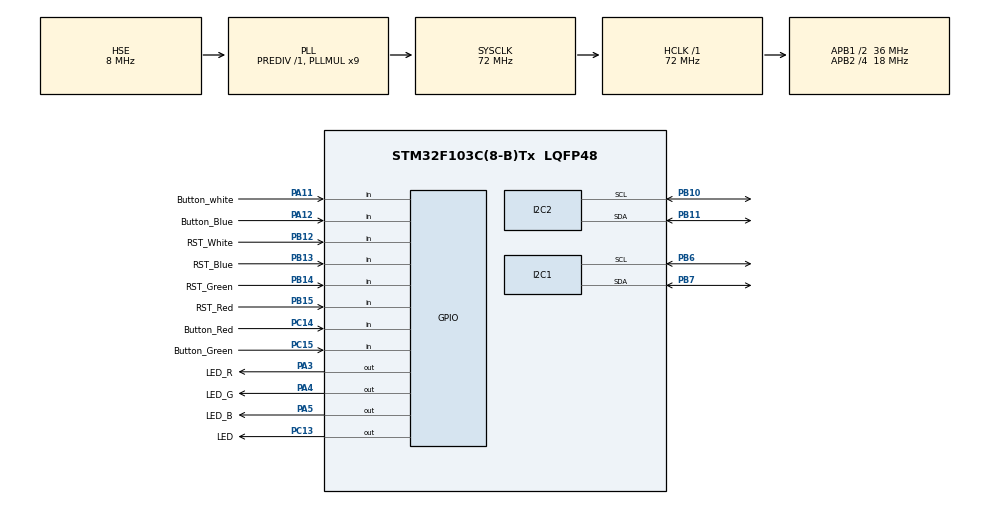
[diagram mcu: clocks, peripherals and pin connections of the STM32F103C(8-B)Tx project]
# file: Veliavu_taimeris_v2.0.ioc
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Mcu.Family=STM32F1
RCC.PLLSourceVirtual=RCC_PLLSOURCE_HSE
PD1-OSC_OUT.Mode=HSE-External-Oscillator
PB10.Mode=I2C
PB14.GPIO_Label=RST_Green
PC13-TAMPER-RTC.Signal=GPIO_Output
PA11.GPIO_Label=Button_white
PD0-OSC_IN.Signal=RCC_OSC_IN
PA11.GPIO_PuPd=GPIO_PULLUP
RCC.APB1CLKDivider=RCC_HCLK_DIV2
PC14-OSC32_IN.Signal=GPIO_Input
PB13.GPIO_Label=RST_Blue
PB11.Signal=I2C2_SDA
PB13.Signal=GPIO_Input
PB15.Signal=GPIO_Input
PC15-OSC32_OUT.GPIO_Label=Button_Green
PA12.GPIO_Label=Button_Blue
RCC.SYSCLKSource=RCC_SYSCLKSOURCE_PLLCLK
ProjectManager.StackSize=0x400
PD1-OSC_OUT.Signal=RCC_OSC_OUT
PA13.Signal=SYS_JTMS-SWDIO
PA12.Signal=GPIO_Input
PB11.Mode=I2C
ProjectManager.TargetToolchain=SW4STM32
RCC.HCLKFreq_Value=72000000
RCC.APB2TimFreq_Value=36000000
PB6.Signal=I2C1_SCL
PB6.Mode=I2C
RCC.USBFreq_Value=72000000
PC15-OSC32_OUT.Signal=GPIO_Input
RCC.AHBFreq_Value=72000000
PD0-OSC_IN.Mode=HSE-External-Oscillator
PB10.Signal=I2C2_SCL
PB14.Signal=GPIO_Input
PA5.Signal=GPIO_Output
board=custom
PC13-TAMPER-RTC.GPIO_Label=LED
RCC.PLLMUL=RCC_PLL_MUL9
PB12.GPIO_Label=RST_White
PB13.GPIO_PuPd=GPIO_PULLUP
RCC.APB2Freq_Value=18000000
PB15.GPIO_Label=RST_Red
PA14.Mode=Serial_Wire
PC15-OSC32_OUT.GPIO_PuPd=GPIO_PULLUP
PB7.Signal=I2C1_SDA
PA13.Mode=Serial_Wire
Mcu.Name=STM32F103C(8-B)Tx
PA4.Signal=GPIO_Output
RCC.SYSCLKFreq_VALUE=72000000
Mcu.Package=LQFP48
PB14.GPIO_PuPd=GPIO_PULLUP
PA5.GPIO_Label=LED_B
PB15.GPIO_PuPd=GPIO_PULLUP
PA11.Signal=GPIO_Input
PB7.Mode=I2C
PA14.Signal=SYS_JTCK-SWCLK
ProjectManager.HeapSize=0x200
NVIC.PriorityGroup=NVIC_PRIORITYGROUP_4
RCC.APB2CLKDivider=RCC_HCLK_DIV4
RCC.APB1TimFreq_Value=72000000
PC14-OSC32_IN.GPIO_PuPd=GPIO_PULLUP
PC14-OSC32_IN.GPIO_Label=Button_Red
PB12.GPIO_PuPd=GPIO_PULLUP
PA12.GPIO_PuPd=GPIO_PULLUP
RCC.APB1Freq_Value=36000000
PA4.GPIO_Label=LED_G
PB12.Signal=GPIO_Input
PA3.GPIO_Label=LED_R
PA3.Signal=GPIO_Output

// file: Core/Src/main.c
/* USER CODE BEGIN Header */
/**
  ******************************************************************************
  * @file           : main.c
  * @brief          : Main program body
  ******************************************************************************
  * @attention
  *
  * <h2><center>&copy; Copyright (c) 2021 STMicroelectronics.
  * All rights reserved.</center></h2>
  *
  * This software component is licensed by ST under BSD 3-Clause license,
  * the "License"; You may not use this file except in compliance with the
  * License. You may obtain a copy of the License at:
  *                        opensource.org/licenses/BSD-3-Clause
  *
  ******************************************************************************
  */
/* USER CODE END Header */
#include "main.h"

/* USER CODE BEGIN Includes */
#include "timer.h"
/* USER CODE END Includes */

I2C_HandleTypeDef hi2c1;
I2C_HandleTypeDef hi2c2;

void SystemClock_Config(void);
static void MX_GPIO_Init(void);
static void MX_I2C1_Init(void);
static void MX_I2C2_Init(void);

int main(void)
{

  /* MCU Configuration--------------------------------------------------------*/

  /* Reset of all peripherals, Initializes the Flash interface and the Systick. */
  HAL_Init();

  /* Configure the system clock */
  SystemClock_Config();

  /* Initialize all configured peripherals */
  MX_GPIO_Init();
  MX_I2C1_Init();
  MX_I2C2_Init();
  /* USER CODE BEGIN 2 */
  timer_ini();
  /* USER CODE END 2 */

  /* Infinite loop */
  /* USER CODE BEGIN WHILE */
  while (1)
  {
	  timer_rst();
	  red_team();
	  timer_rst();
	  green_team();
	  timer_rst();
	  blue_team();
	  timer_rst();
	  white_team();
    /* USER CODE END WHILE */

  }
}

void SystemClock_Config(void)
{
  RCC_OscInitTypeDef RCC_OscInitStruct = {0};
  RCC_ClkInitTypeDef RCC_ClkInitStruct = {0};

  /** Initializes the RCC Oscillators according to the specified parameters
  * in the RCC_OscInitTypeDef structure.
  */
  RCC_OscInitStruct.OscillatorType = RCC_OSCILLATORTYPE_HSE;
  RCC_OscInitStruct.HSEState = RCC_HSE_ON;
  RCC_OscInitStruct.HSEPredivValue = RCC_HSE_PREDIV_DIV1;
  RCC_OscInitStruct.HSIState = RCC_HSI_ON;
  RCC_OscInitStruct.PLL.PLLState = RCC_PLL_ON;
  RCC_OscInitStruct.PLL.PLLSource = RCC_PLLSOURCE_HSE;
  RCC_OscInitStruct.PLL.PLLMUL = RCC_PLL_MUL9;
  if (HAL_RCC_OscConfig(&RCC_OscInitStruct) != HAL_OK)
  {
    Error_Handler();
  }
  /** Initializes the CPU, AHB and APB buses clocks
  */
  RCC_ClkInitStruct.ClockType = RCC_CLOCKTYPE_HCLK|RCC_CLOCKTYPE_SYSCLK
                              |RCC_CLOCKTYPE_PCLK1|RCC_CLOCKTYPE_PCLK2;
  RCC_ClkInitStruct.SYSCLKSource = RCC_SYSCLKSOURCE_PLLCLK;
  RCC_ClkInitStruct.AHBCLKDivider = RCC_SYSCLK_DIV1;
  RCC_ClkInitStruct.APB1CLKDivider = RCC_HCLK_DIV2;
  RCC_ClkInitStruct.APB2CLKDivider = RCC_HCLK_DIV4;

  if (HAL_RCC_ClockConfig(&RCC_ClkInitStruct, FLASH_LATENCY_2) != HAL_OK)
  {
    Error_Handler();
  }
}

static void MX_I2C1_Init(void)
{

  hi2c1.Instance = I2C1;
  hi2c1.Init.ClockSpeed = 100000;
  hi2c1.Init.DutyCycle = I2C_DUTYCYCLE_2;
  hi2c1.Init.OwnAddress1 = 0;
  hi2c1.Init.AddressingMode = I2C_ADDRESSINGMODE_7BIT;
  hi2c1.Init.DualAddressMode = I2C_DUALADDRESS_DISABLE;
  hi2c1.Init.OwnAddress2 = 0;
  hi2c1.Init.GeneralCallMode = I2C_GENERALCALL_DISABLE;
  hi2c1.Init.NoStretchMode = I2C_NOSTRETCH_DISABLE;
  if (HAL_I2C_Init(&hi2c1) != HAL_OK)
  {
    Error_Handler();
  }

}

static void MX_I2C2_Init(void)
{

  hi2c2.Instance = I2C2;
  hi2c2.Init.ClockSpeed = 100000;
  hi2c2.Init.DutyCycle = I2C_DUTYCYCLE_2;
  hi2c2.Init.OwnAddress1 = 0;
  hi2c2.Init.AddressingMode = I2C_ADDRESSINGMODE_7BIT;
  hi2c2.Init.DualAddressMode = I2C_DUALADDRESS_DISABLE;
  hi2c2.Init.OwnAddress2 = 0;
  hi2c2.Init.GeneralCallMode = I2C_GENERALCALL_DISABLE;
  hi2c2.Init.NoStretchMode = I2C_NOSTRETCH_DISABLE;
  if (HAL_I2C_Init(&hi2c2) != HAL_OK)
  {
    Error_Handler();
  }

}

static void MX_GPIO_Init(void)
{
  GPIO_InitTypeDef GPIO_InitStruct = {0};

  /* GPIO Ports Clock Enable */
  __HAL_RCC_GPIOC_CLK_ENABLE();
  __HAL_RCC_GPIOD_CLK_ENABLE();
  __HAL_RCC_GPIOA_CLK_ENABLE();
  __HAL_RCC_GPIOB_CLK_ENABLE();

  /*Configure GPIO pin Output Level */
  HAL_GPIO_WritePin(LED_GPIO_Port, LED_Pin, GPIO_PIN_RESET);

  /*Configure GPIO pin Output Level */
  HAL_GPIO_WritePin(GPIOA, LED_R_Pin|LED_G_Pin|LED_B_Pin, GPIO_PIN_RESET);

  /*Configure GPIO pin : LED_Pin */
  GPIO_InitStruct.Pin = LED_Pin;
  GPIO_InitStruct.Mode = GPIO_MODE_OUTPUT_PP;
  GPIO_InitStruct.Pull = GPIO_NOPULL;
  GPIO_InitStruct.Speed = GPIO_SPEED_FREQ_LOW;
  HAL_GPIO_Init(LED_GPIO_Port, &GPIO_InitStruct);

  /*Configure GPIO pins : Button_Red_Pin Button_Green_Pin */
  GPIO_InitStruct.Pin = Button_Red_Pin|Button_Green_Pin;
  GPIO_InitStruct.Mode = GPIO_MODE_INPUT;
  GPIO_InitStruct.Pull = GPIO_PULLUP;
  HAL_GPIO_Init(GPIOC, &GPIO_InitStruct);

  /*Configure GPIO pins : LED_R_Pin LED_G_Pin LED_B_Pin */
  GPIO_InitStruct.Pin = LED_R_Pin|LED_G_Pin|LED_B_Pin;
  GPIO_InitStruct.Mode = GPIO_MODE_OUTPUT_PP;
  GPIO_InitStruct.Pull = GPIO_NOPULL;
  GPIO_InitStruct.Speed = GPIO_SPEED_FREQ_LOW;
  HAL_GPIO_Init(GPIOA, &GPIO_InitStruct);

  /*Configure GPIO pins : RST_White_Pin RST_Blue_Pin RST_Green_Pin RST_Red_Pin */
  GPIO_InitStruct.Pin = RST_White_Pin|RST_Blue_Pin|RST_Green_Pin|RST_Red_Pin;
  GPIO_InitStruct.Mode = GPIO_MODE_INPUT;
  GPIO_InitStruct.Pull = GPIO_PULLUP;
  HAL_GPIO_Init(GPIOB, &GPIO_InitStruct);

  /*Configure GPIO pins : Button_white_Pin Button_Blue_Pin */
  GPIO_InitStruct.Pin = Button_white_Pin|Button_Blue_Pin;
  GPIO_InitStruct.Mode = GPIO_MODE_INPUT;
  GPIO_InitStruct.Pull = GPIO_PULLUP;
  HAL_GPIO_Init(GPIOA, &GPIO_InitStruct);

}

void Error_Handler(void)
{
  __disable_irq();
  while (1)
  {
  }
}

/************************ (C) COPYRIGHT STMicroelectronics *****END OF FILE****/
